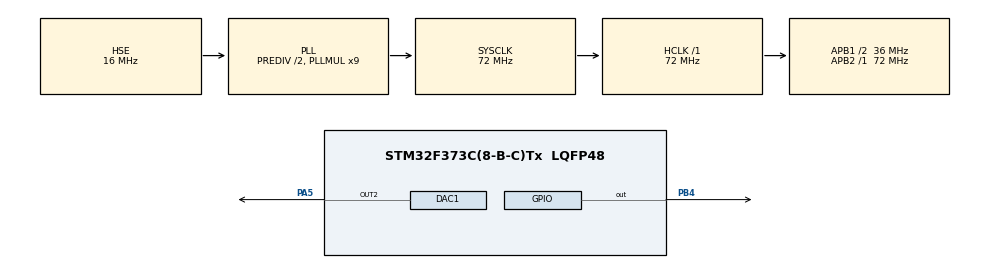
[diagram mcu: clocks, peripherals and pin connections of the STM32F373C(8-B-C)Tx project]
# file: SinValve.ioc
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Dma.DAC1_CH2.0.Direction=DMA_MEMORY_TO_PERIPH
Dma.DAC1_CH2.0.Instance=DMA1_Channel4
Dma.DAC1_CH2.0.MemDataAlignment=DMA_MDATAALIGN_HALFWORD
Dma.DAC1_CH2.0.MemInc=DMA_MINC_ENABLE
Dma.DAC1_CH2.0.Mode=DMA_CIRCULAR
Dma.DAC1_CH2.0.PeriphDataAlignment=DMA_PDATAALIGN_HALFWORD
Dma.DAC1_CH2.0.PeriphInc=DMA_PINC_DISABLE
Dma.DAC1_CH2.0.Priority=DMA_PRIORITY_LOW
Dma.Request0=DAC1_CH2
Mcu.Family=STM32F3
Mcu.Name=STM32F373C(8-B-C)Tx
Mcu.Package=LQFP48
Mcu.UserConstants=period,(72000000/UPDATE_FREQ)-1;SinGenTimer,$$_TIM6_IP_HANDLE_$$;SAMPLE_COUNT,250;SIN_FREQ,100;UPDATE_FREQ,(SIN_FREQ * SAMPLE_COUNT)
NVIC.PriorityGroup=NVIC_PRIORITYGROUP_4
NVIC.TIM6_DAC1_IRQn=true\:0\:0\:false\:false\:true\:true\:true\:true
PA13.Mode=Serial_Wire
PA13.Signal=SYS_JTMS-SWDIO
PA14.Mode=Serial_Wire
PA14.Signal=SYS_JTCK-SWCLK
PA5.Signal=COMP_DAC12_group
PB4.Signal=GPIO_Output
PF0-OSC_IN.Mode=HSE-External-Oscillator
PF0-OSC_IN.Signal=RCC_OSC_IN
PF1-OSC_OUT.Mode=HSE-External-Oscillator
PF1-OSC_OUT.Signal=RCC_OSC_OUT
ProjectManager.HeapSize=0x200
ProjectManager.StackSize=0x400
ProjectManager.TargetToolchain=STM32CubeIDE
RCC.AHBFreq_Value=72000000
RCC.APB1CLKDivider=RCC_HCLK_DIV2
RCC.APB1Freq_Value=36000000
RCC.APB1TimFreq_Value=72000000
RCC.APB2Freq_Value=72000000
RCC.APB2TimFreq_Value=72000000
RCC.CortexFreq_Value=72000000
RCC.HCLKFreq_Value=72000000
RCC.HSE_VALUE=16000000
RCC.HSI_VALUE=8000000
RCC.LSE_VALUE=32768
RCC.PLLMUL=RCC_PLL_MUL9
RCC.PLLSourceVirtual=RCC_PLLSOURCE_HSE
RCC.PRESCALERUSB=RCC_USBCLKSOURCE_PLL_DIV1_5
RCC.RCC_PLLsource_Clock_Source_FROM_HSE=RCC_HSE_PREDIV_DIV2
RCC.SYSCLKFreq_VALUE=72000000
RCC.SYSCLKSource=RCC_SYSCLKSOURCE_PLLCLK
RCC.USBFreq_Value=48000000
SH.COMP_DAC12_group.0=DAC1_OUT2,Enable_DAC_OUT2
TIM6.AutoReloadPreload=TIM_AUTORELOAD_PRELOAD_ENABLE
TIM6.Period=period
TIM6.TIM_MasterOutputTrigger=TIM_TRGO_RESET
VP_TIM6_VS_ClockSourceINT.Mode=Enable_Timer
board=custom

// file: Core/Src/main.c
/* USER CODE BEGIN Header */
/**
  ******************************************************************************
  * @file           : main.c
  * @brief          : Main program body
  ******************************************************************************
  * @attention
  *
  * Copyright (c) 2025 STMicroelectronics.
  * All rights reserved.
  *
  * This software is licensed under terms that can be found in the LICENSE file
  * in the root directory of this software component.
  * If no LICENSE file comes with this software, it is provided AS-IS.
  *
  ******************************************************************************
  */
/* USER CODE END Header */
#include "main.h"
#include "dac.h"
#include "dma.h"
#include "tim.h"
#include "gpio.h"

/* USER CODE BEGIN Includes */
#include <math.h>  // Добавляем для математических функций
/* USER CODE END Includes */

void SystemClock_Config(void);
/* USER CODE BEGIN PFP */
void generate_sine_wave(void);
/* USER CODE END PFP */

int main(void)
{

  /* MCU Configuration--------------------------------------------------------*/

  /* Reset of all peripherals, Initializes the Flash interface and the Systick. */
  HAL_Init();

  /* Configure the system clock */
  SystemClock_Config();

  /* USER CODE BEGIN SysInit */
  generate_sine_wave();

  /* USER CODE END SysInit */

  /* Initialize all configured peripherals */
  MX_GPIO_Init();
  MX_DMA_Init();
  MX_DAC1_Init();
  MX_TIM6_Init();
  /* USER CODE BEGIN 2 */

  tim6_set_update_hz(0.1);

  HAL_TIM_Base_Start_IT(&htim6);
  HAL_DAC_Start(&hdac1, DAC_CHANNEL_2);

  /* USER CODE END 2 */

  /* Infinite loop */
  /* USER CODE BEGIN WHILE */
  while (1)
  {
	  __NOP();
    /* USER CODE END WHILE */

  }
}

void SystemClock_Config(void)
{
  RCC_OscInitTypeDef RCC_OscInitStruct = {0};
  RCC_ClkInitTypeDef RCC_ClkInitStruct = {0};

  /** Initializes the RCC Oscillators according to the specified parameters
  * in the RCC_OscInitTypeDef structure.
  */
  RCC_OscInitStruct.OscillatorType = RCC_OSCILLATORTYPE_HSE;
  RCC_OscInitStruct.HSEState = RCC_HSE_ON;
  RCC_OscInitStruct.HSEPredivValue = RCC_HSE_PREDIV_DIV2;
  RCC_OscInitStruct.HSIState = RCC_HSI_ON;
  RCC_OscInitStruct.PLL.PLLState = RCC_PLL_ON;
  RCC_OscInitStruct.PLL.PLLSource = RCC_PLLSOURCE_HSE;
  RCC_OscInitStruct.PLL.PLLMUL = RCC_PLL_MUL9;
  if (HAL_RCC_OscConfig(&RCC_OscInitStruct) != HAL_OK)
  {
    Error_Handler();
  }

  /** Initializes the CPU, AHB and APB buses clocks
  */
  RCC_ClkInitStruct.ClockType = RCC_CLOCKTYPE_HCLK|RCC_CLOCKTYPE_SYSCLK
                              |RCC_CLOCKTYPE_PCLK1|RCC_CLOCKTYPE_PCLK2;
  RCC_ClkInitStruct.SYSCLKSource = RCC_SYSCLKSOURCE_PLLCLK;
  RCC_ClkInitStruct.AHBCLKDivider = RCC_SYSCLK_DIV1;
  RCC_ClkInitStruct.APB1CLKDivider = RCC_HCLK_DIV2;
  RCC_ClkInitStruct.APB2CLKDivider = RCC_HCLK_DIV1;

  if (HAL_RCC_ClockConfig(&RCC_ClkInitStruct, FLASH_LATENCY_2) != HAL_OK)
  {
    Error_Handler();
  }
}

/* USER CODE END 4 */

void Error_Handler(void)
{
  __disable_irq();
  while (1)
  {
  }
}
